VERSION ""

NS_ :

BS_:

BU_: ZCUR HCM_L HCM_R RLLM_Fix RRLM_Fix RLM_Move Trailer

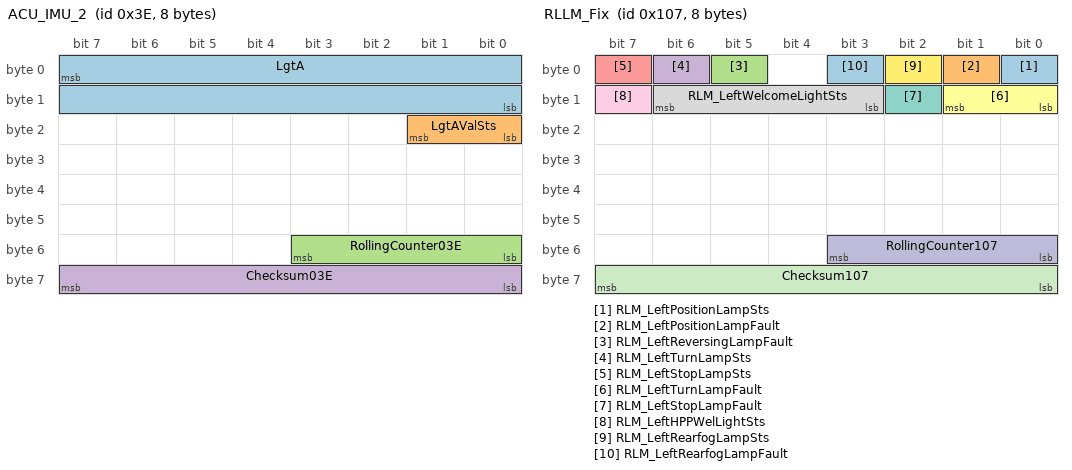
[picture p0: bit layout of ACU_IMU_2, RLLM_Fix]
BO_ 62 ACU_IMU_2: 8 ZCUR
 SG_ LgtA : 7|16@0+ (0.001,-2) [-2|2] "g" HCM_L,HCM_R
 SG_ LgtAValSts : 17|2@0+ (1,0) [0|3] "" HCM_L,HCM_R
 SG_ RollingCounter03E : 51|4@0+ (1,0) [0|15] "" HCM_L,HCM_R
 SG_ Checksum03E : 63|8@0+ (1,0) [0|255] "" HCM_L,HCM_R

BO_ 98 BCM_state3: 8 ZCUR
 SG_ BCM_AdasBlueLampReq : 1|2@0+ (1,0) [0|3] "" RLLM_Fix,RRLM_Fix,RLM_Move

BO_ 256 HCM_L: 8 HCM_L
 SG_ HCM_LeftpositionLampSts : 0|1@0+ (1,0) [0|1] "" ZCUR
 SG_ HCM_LeftpositionLampFault : 1|1@0+ (1,0) [0|1] "" ZCUR
 SG_ HCM_LeftDRLSts : 2|1@0+ (1,0) [0|1] "" ZCUR
 SG_ HCM_LeftDRLFault : 3|1@0+ (1,0) [0|1] "" ZCUR
 SG_ HCM_middleLeftPositionLampSts : 4|1@0+ (1,0) [0|1] "" ZCUR
 SG_ HCM_middleLeftPositionLampFault : 5|1@0+ (1,0) [0|1] "" ZCUR
 SG_ HCM_LeftLowBeamSts : 6|1@0+ (1,0) [0|1] "" ZCUR
 SG_ HCM_LeftLowBeamFault : 7|1@0+ (1,0) [0|1] "" ZCUR
 SG_ HCM_LeftHighBeamSts : 8|1@0+ (1,0) [0|1] "" ZCUR
 SG_ HCM_LeftHighBeamFault : 9|1@0+ (1,0) [0|1] "" ZCUR
 SG_ HCM_hcmHeightSetLt : 12|3@0+ (1,0) [0|7] "" ZCUR
 SG_ HCM_LeftTurnLampSts : 13|1@0+ (1,0) [0|1] "" ZCUR
 SG_ HCM_LeftTurnLampFault : 15|2@0+ (1,0) [0|3] "" ZCUR
 SG_ HCM_LeftWelcomeLightSts : 19|4@0+ (1,0) [0|15] "" ZCUR
 SG_ HCM_leftADBModeSts : 21|2@0+ (1,0) [0|3] "" ZCUR
 SG_ HCM_middleRightPositionLampFault : 22|1@0+ (1,0) [0|1] "" ZCUR
 SG_ HCM_middleRightPositionLampSts : 23|1@0+ (1,0) [0|1] "" ZCUR
 SG_ HCM_LeftInputVoltage : 29|6@0+ (1,0) [6|63] "V" ZCUR
 SG_ HCM_LeftHPPWelLightSts : 31|1@0+ (1,0) [0|1] "" ZCUR
 SG_ HCM_LeftMatrixLEDunitFault : 32|1@0+ (1,0) [0|1] "" ZCUR
 SG_ HCM_LeftAutoHeightAdjustFault : 33|1@0+ (1,0) [0|1] "" ZCUR
 SG_ HCM_LeftAFSFault : 34|1@0+ (1,0) [0|1] "" ZCUR
 SG_ HCM_WelcomeMusicEnable : 36|2@0+ (1,0) [0|3] "" ZCUR
 SG_ HCM_AlsHeightSet : 47|8@0+ (1,0) [0|255] "" ZCUR,HCM_R
 SG_ RollingCounter100 : 51|4@0+ (1,0) [0|15] "" ZCUR
 SG_ Checksum100 : 63|8@0+ (1,0) [0|255] "" ZCUR
 SG_ HCM_FLFogLampSts : 52|1@0+ (1,0) [0|1] "" ZCUR
 SG_ HCM_FLFogLampFault : 53|1@0+ (1,0) [0|1] "" ZCUR

BO_ 263 RLLM_Fix: 8 RLLM_Fix
 SG_ RLM_LeftPositionLampSts : 0|1@0+ (1,0) [0|1] "" ZCUR,RRLM_Fix
 SG_ RLM_LeftPositionLampFault : 1|1@0+ (1,0) [0|1] "" ZCUR,RRLM_Fix
 SG_ RLM_LeftReversingLampFault : 5|1@0+ (1,0) [0|1] "" ZCUR,RRLM_Fix
 SG_ RLM_LeftTurnLampSts : 6|1@0+ (1,0) [0|1] "" ZCUR,RRLM_Fix
 SG_ RLM_LeftStopLampSts : 7|1@0+ (1,0) [0|1] "" ZCUR,RRLM_Fix
 SG_ RLM_LeftTurnLampFault : 9|2@0+ (1,0) [0|3] "" ZCUR,RRLM_Fix
 SG_ RLM_LeftStopLampFault : 10|1@0+ (1,0) [0|1] "" ZCUR,RRLM_Fix
 SG_ RLM_LeftWelcomeLightSts : 14|4@0+ (1,0) [0|15] "" ZCUR,RRLM_Fix
 SG_ RLM_LeftHPPWelLightSts : 15|1@0+ (1,0) [0|1] "" ZCUR,RRLM_Fix
 SG_ RollingCounter107 : 51|4@0+ (1,0) [0|15] "" ZCUR
 SG_ Checksum107 : 63|8@0+ (1,0) [0|255] "" ZCUR
 SG_ RLM_LeftRearfogLampSts : 2|1@0+ (1,0) [0|1] "" ZCUR
 SG_ RLM_LeftRearfogLampFault : 3|1@0+ (1,0) [0|1] "" ZCUR

BO_ 264 RLM_Move: 8 RLM_Move
 SG_ RLM_MidpositionLampSts : 0|1@0+ (1,0) [0|1] "" ZCUR,RLLM_Fix,RRLM_Fix
 SG_ RLM_MidApositionLampFault : 1|1@0+ (1,0) [0|1] "" ZCUR,RLLM_Fix,RRLM_Fix
 SG_ RLM_MidLeftTurnLampSts : 2|1@0+ (1,0) [0|1] "" ZCUR,RLLM_Fix,RRLM_Fix
 SG_ RLM_MidStopLampSts : 3|1@0+ (1,0) [0|1] "" ZCUR,RLLM_Fix,RRLM_Fix
 SG_ RLM_MidLeftTurnLampFault : 5|2@0+ (1,0) [0|3] "" ZCUR,RLLM_Fix,RRLM_Fix
 SG_ RLM_MidLeftStopLampFault : 6|1@0+ (1,0) [0|1] "" ZCUR,RLLM_Fix,RRLM_Fix
 SG_ RLM_MidRightTurnLampSts : 7|1@0+ (1,0) [0|1] "" ZCUR,RLLM_Fix,RRLM_Fix
 SG_ RLM_LicenseLampFault : 8|1@0+ (1,0) [0|1] "" ZCUR,RLLM_Fix,RRLM_Fix
 SG_ RLM_LicenseLampSts : 9|1@0+ (1,0) [0|1] "" ZCUR,RLLM_Fix,RRLM_Fix
 SG_ RLM_ReversingLampFault : 10|1@0+ (1,0) [0|1] "" ZCUR,RLLM_Fix,RRLM_Fix
 SG_ RLM_ReverseLampSts : 11|1@0+ (1,0) [0|1] "" ZCUR,RLLM_Fix,RRLM_Fix
 SG_ RLM_HighStopLampFault : 12|1@0+ (1,0) [0|1] "" ZCUR,RLLM_Fix,RRLM_Fix
 SG_ RLM_HighStopLampSts : 13|1@0+ (1,0) [0|1] "" ZCUR,RLLM_Fix,RRLM_Fix
 SG_ RLM_MidRightTurnLampFault : 15|2@0+ (1,0) [0|3] "" ZCUR,RLLM_Fix,RRLM_Fix
 SG_ RLM_HPPWelLightSts : 19|1@0+ (1,0) [0|1] "" ZCUR,RLLM_Fix,RRLM_Fix
 SG_ RLM_WelcomeLightSts : 23|4@0+ (1,0) [0|15] "" ZCUR,RLLM_Fix,RRLM_Fix
 SG_ RLM_MidRightPositionLampSts : 18|1@0+ (1,0) [0|1] "" ZCUR
 SG_ RLM_MidRightPositionLampFault : 17|1@0+ (1,0) [0|1] "" ZCUR
 SG_ RollingCounter108 : 51|4@0+ (1,0) [0|15] "" ZCUR
 SG_ Checksum108 : 63|8@0+ (1,0) [0|255] "" ZCUR

BO_ 272 HCM_R: 8 HCM_R
 SG_ HCM_RightpositionLampSts : 0|1@0+ (1,0) [0|1] "" ZCUR
 SG_ HCM_RightpositionLampFault : 1|1@0+ (1,0) [0|1] "" ZCUR
 SG_ HCM_RightDRLSts : 2|1@0+ (1,0) [0|1] "" ZCUR
 SG_ HCM_RightDRLFault : 3|1@0+ (1,0) [0|1] "" ZCUR
 SG_ HCM_RightLowBeamSts : 6|1@0+ (1,0) [0|1] "" ZCUR
 SG_ HCM_RightLowBeamFault : 7|1@0+ (1,0) [0|1] "" ZCUR
 SG_ HCM_RightHighBeamSts : 8|1@0+ (1,0) [0|1] "" ZCUR
 SG_ HCM_RightHighBeamFault : 9|1@0+ (1,0) [0|1] "" ZCUR
 SG_ HCM_hcmHeightSetRt : 12|3@0+ (1,0) [0|7] "" ZCUR
 SG_ HCM_RightTurnLampSts : 13|1@0+ (1,0) [0|1] "" ZCUR
 SG_ HCM_RightTurnLampFault : 15|2@0+ (1,0) [0|3] "" ZCUR
 SG_ HCM_RightHPPWelLightSts : 17|1@0+ (1,0) [0|1] "" ZCUR
 SG_ HCM_RightWelcomeLightSts : 21|4@0+ (1,0) [0|15] "" ZCUR
 SG_ HCM_rightADBModeSts : 23|2@0+ (1,0) [0|3] "" ZCUR
 SG_ HCM_RightMatrixLEDunitFault : 24|1@0+ (1,0) [0|1] "" ZCUR
 SG_ HCM_RightAutoHeightAdjustFault : 25|1@0+ (1,0) [0|1] "" ZCUR
 SG_ HCM_RightAFSFault : 26|1@0+ (1,0) [0|1] "" ZCUR
 SG_ HCM_RightInputVoltage : 37|6@0+ (1,0) [6|63] "V" ZCUR
 SG_ RollingCounter110 : 51|4@0+ (1,0) [0|15] "" ZCUR
 SG_ Checksum110 : 63|8@0+ (1,0) [0|255] "" ZCUR
 SG_ HCM_FRFogLampSts : 27|1@0+ (1,0) [0|1] "" ZCUR
 SG_ HCM_FRFogLampFault : 28|1@0+ (1,0) [0|1] "" ZCUR

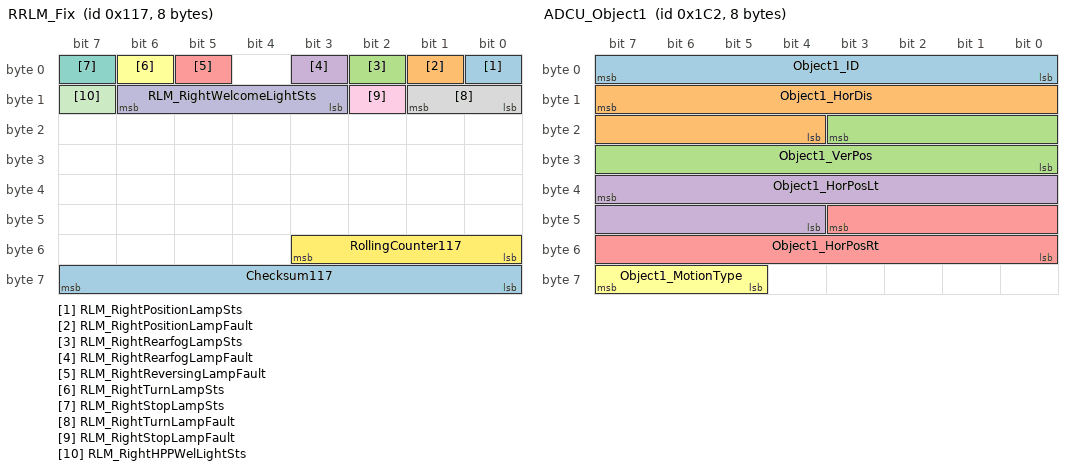
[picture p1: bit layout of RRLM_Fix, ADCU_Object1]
BO_ 279 RRLM_Fix: 8 RRLM_Fix
 SG_ RLM_RightPositionLampSts : 0|1@0+ (1,0) [0|1] "" ZCUR,RLM_Move
 SG_ RLM_RightPositionLampFault : 1|1@0+ (1,0) [0|1] "" ZCUR,RLM_Move
 SG_ RLM_RightRearfogLampSts : 2|1@0+ (1,0) [0|1] "" ZCUR,RLM_Move
 SG_ RLM_RightRearfogLampFault : 3|1@0+ (1,0) [0|1] "" ZCUR,RLM_Move
 SG_ RLM_RightReversingLampFault : 5|1@0+ (1,0) [0|1] "" ZCUR,RLM_Move
 SG_ RLM_RightTurnLampSts : 6|1@0+ (1,0) [0|1] "" ZCUR,RLM_Move
 SG_ RLM_RightStopLampSts : 7|1@0+ (1,0) [0|1] "" ZCUR,RLM_Move
 SG_ RLM_RightTurnLampFault : 9|2@0+ (1,0) [0|3] "" ZCUR,RLM_Move
 SG_ RLM_RightStopLampFault : 10|1@0+ (1,0) [0|1] "" ZCUR,RLM_Move
 SG_ RLM_RightWelcomeLightSts : 14|4@0+ (1,0) [0|15] "" ZCUR,RLM_Move
 SG_ RLM_RightHPPWelLightSts : 15|1@0+ (1,0) [0|1] "" ZCUR,RLM_Move
 SG_ RollingCounter117 : 51|4@0+ (1,0) [0|15] "" ZCUR,RLM_Move
 SG_ Checksum117 : 63|8@0+ (1,0) [0|255] "" ZCUR,RLM_Move

BO_ 450 ADCU_Object1: 8 ZCUR
 SG_ Object1_ID : 7|8@0+ (1,0) [0|250] "" HCM_L,HCM_R
 SG_ Object1_HorDis : 15|12@0+ (0.1,-30) [-30|30] "m" HCM_L,HCM_R
 SG_ Object1_VerPos : 19|12@0+ (0.2,0) [0|800] "m" HCM_L,HCM_R
 SG_ Object1_HorPosLt : 39|12@0+ (0.02,-40) [-40|40] "degree" HCM_L,HCM_R
 SG_ Object1_HorPosRt : 43|12@0+ (0.02,-40) [-40|40] "degree" HCM_L,HCM_R
 SG_ Object1_MotionType : 63|3@0+ (1,0) [0|7] "" HCM_L,HCM_R

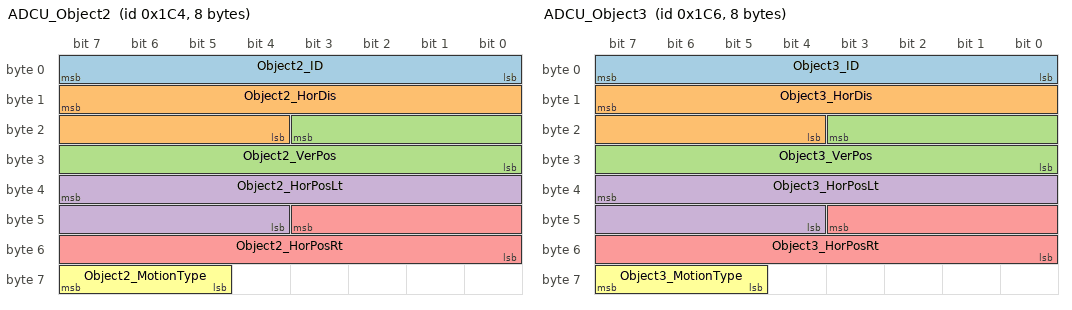
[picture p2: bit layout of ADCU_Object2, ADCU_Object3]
BO_ 452 ADCU_Object2: 8 ZCUR
 SG_ Object2_ID : 7|8@0+ (1,0) [0|250] "" HCM_L,HCM_R
 SG_ Object2_HorDis : 15|12@0+ (0.1,-30) [-30|30] "m" HCM_L,HCM_R
 SG_ Object2_VerPos : 19|12@0+ (0.2,0) [0|800] "m" HCM_L,HCM_R
 SG_ Object2_HorPosLt : 39|12@0+ (0.02,-40) [-40|40] "degree" HCM_L,HCM_R
 SG_ Object2_HorPosRt : 43|12@0+ (0.02,-40) [-40|40] "degree" HCM_L,HCM_R
 SG_ Object2_MotionType : 63|3@0+ (1,0) [0|7] "" HCM_L,HCM_R

BO_ 454 ADCU_Object3: 8 ZCUR
 SG_ Object3_ID : 7|8@0+ (1,0) [0|250] "" HCM_L,HCM_R
 SG_ Object3_HorDis : 15|12@0+ (0.1,-30) [-30|30] "m" HCM_L,HCM_R
 SG_ Object3_VerPos : 19|12@0+ (0.2,0) [0|800] "m" HCM_L,HCM_R
 SG_ Object3_HorPosLt : 39|12@0+ (0.02,-40) [-40|40] "degree" HCM_L,HCM_R
 SG_ Object3_HorPosRt : 43|12@0+ (0.02,-40) [-40|40] "degree" HCM_L,HCM_R
 SG_ Object3_MotionType : 63|3@0+ (1,0) [0|7] "" HCM_L,HCM_R

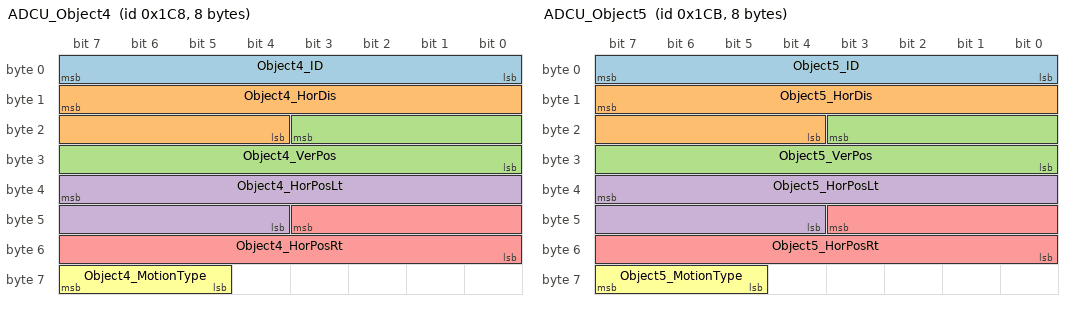
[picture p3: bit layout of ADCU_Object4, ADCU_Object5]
BO_ 456 ADCU_Object4: 8 ZCUR
 SG_ Object4_ID : 7|8@0+ (1,0) [0|250] "" HCM_L,HCM_R
 SG_ Object4_HorDis : 15|12@0+ (0.1,-30) [-30|30] "m" HCM_L,HCM_R
 SG_ Object4_VerPos : 19|12@0+ (0.2,0) [0|800] "m" HCM_L,HCM_R
 SG_ Object4_HorPosLt : 39|12@0+ (0.02,-40) [-40|40] "degree" HCM_L,HCM_R
 SG_ Object4_HorPosRt : 43|12@0+ (0.02,-40) [-40|40] "degree" HCM_L,HCM_R
 SG_ Object4_MotionType : 63|3@0+ (1,0) [0|7] "" HCM_L,HCM_R

BO_ 459 ADCU_Object5: 8 ZCUR
 SG_ Object5_ID : 7|8@0+ (1,0) [0|250] "" HCM_L,HCM_R
 SG_ Object5_HorDis : 15|12@0+ (0.1,-30) [-30|30] "m" HCM_L,HCM_R
 SG_ Object5_VerPos : 19|12@0+ (0.2,0) [0|800] "m" HCM_L,HCM_R
 SG_ Object5_HorPosLt : 39|12@0+ (0.02,-40) [-40|40] "degree" HCM_L,HCM_R
 SG_ Object5_HorPosRt : 43|12@0+ (0.02,-40) [-40|40] "degree" HCM_L,HCM_R
 SG_ Object5_MotionType : 63|3@0+ (1,0) [0|7] "" HCM_L,HCM_R

BO_ 471 IVI_ACHCMCtrl: 8 ZCUR
 SG_ ivi_hcmHeightSet : 47|3@0+ (1,0) [0|7] "" HCM_L,HCM_R
 SG_ IVI_hcmHeightAdjustSet : 54|2@0+ (1,0) [0|3] "" HCM_L,HCM_R

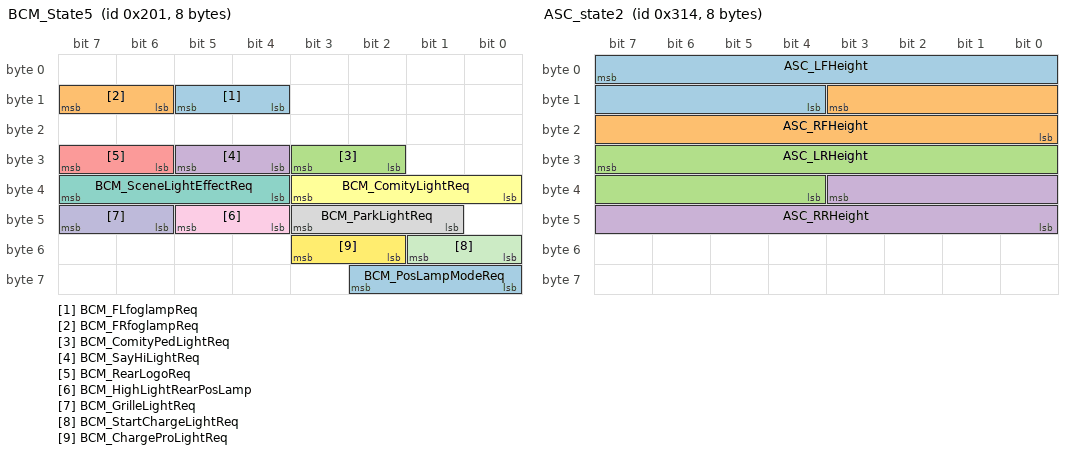
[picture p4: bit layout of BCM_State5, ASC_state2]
BO_ 513 BCM_State5: 8 ZCUR
 SG_ BCM_FLfoglampReq : 13|2@0+ (1,0) [0|3] "" HCM_L
 SG_ BCM_FRfoglampReq : 15|2@0+ (1,0) [0|3] "" HCM_R
 SG_ BCM_ComityPedLightReq : 27|2@0+ (1,0) [0|3] "" HCM_L,HCM_R,RLLM_Fix,RRLM_Fix,RLM_Move
 SG_ BCM_SayHiLightReq : 29|2@0+ (1,0) [0|3] "" HCM_L,HCM_R,RLLM_Fix,RRLM_Fix,RLM_Move
 SG_ BCM_RearLogoReq : 31|2@0+ (1,0) [0|3] "" RLM_Move
 SG_ BCM_ComityLightReq : 35|4@0+ (1,0) [0|15] "" HCM_L,HCM_R,RLLM_Fix,RRLM_Fix,RLM_Move
 SG_ BCM_SceneLightEffectReq : 39|4@0+ (1,0) [0|15] "" HCM_L,HCM_R,RLLM_Fix,RRLM_Fix,RLM_Move
 SG_ BCM_ParkLightReq : 43|3@0+ (1,0) [0|7] "" HCM_L,HCM_R,RLLM_Fix,RRLM_Fix,RLM_Move
 SG_ BCM_HighLightRearPosLamp : 45|2@0+ (1,0) [0|3] "" RLLM_Fix,RRLM_Fix,RLM_Move
 SG_ BCM_GrilleLightReq : 47|2@0+ (1,0) [0|3] "" Vector__XXX
 SG_ BCM_StartChargeLightReq : 49|2@0+ (1,0) [0|3] "" HCM_L,HCM_R,RLLM_Fix,RRLM_Fix,RLM_Move
 SG_ BCM_ChargeProLightReq : 51|2@0+ (1,0) [0|3] "" HCM_L,HCM_R,RLLM_Fix,RRLM_Fix,RLM_Move
 SG_ BCM_PosLampModeReq : 58|3@0+ (1,0) [0|7] "" RLLM_Fix,RRLM_Fix,RLM_Move

BO_ 673 BCM_state: 8 ZCUR
 SG_ BCM_RMPosLampReq : 1|2@0+ (1,0) [0|3] "" RLM_Move
 SG_ BCM_FLdrlReq : 3|2@0+ (1,0) [0|3] "" HCM_L
 SG_ BCM_EXLHeightAdjtReq : 11|3@0+ (1,0) [0|7] "" HCM_L,HCM_R
 SG_ BCM_ADBModeReq : 13|2@0+ (1,0) [0|3] "" HCM_L,HCM_R
 SG_ BCM_FLPosLampReq : 15|2@0+ (1,0) [0|3] "" HCM_L,HCM_R
 SG_ BCM_FRdrlReq : 17|2@0+ (1,0) [0|3] "" HCM_R
 SG_ BCM_FRPosLampReq : 19|2@0+ (1,0) [0|3] "" HCM_L,HCM_R
 SG_ BCM_LowBeamReq : 21|2@0+ (1,0) [0|3] "" HCM_L,HCM_R
 SG_ BCM_HighBeamReq : 23|2@0+ (1,0) [0|3] "" HCM_L,HCM_R
 SG_ BCM_RearfoglampReq : 27|2@0+ (1,0) [0|3] "" RRLM_Fix,Trailer
 SG_ BCM_LeftTurnLampReq : 29|2@0+ (1,0) [0|3] "" HCM_L,RLLM_Fix,RLM_Move,Trailer
 SG_ BCM_RightTurnLampReq : 31|2@0+ (1,0) [0|3] "" HCM_R,RRLM_Fix,RLM_Move,Trailer
 SG_ BCM_RLPosLampReq : 33|2@0+ (1,0) [0|3] "" RLLM_Fix,Trailer
 SG_ BCM_RRPosLampReq : 35|2@0+ (1,0) [0|3] "" RRLM_Fix,Trailer
 SG_ BCM_turnLampFlickerReq : 37|2@0+ (1,0) [0|3] "" HCM_L,HCM_R,RLLM_Fix,RRLM_Fix,RLM_Move
 SG_ BCM_turnLampSerialReq : 39|2@0+ (1,0) [0|3] "" HCM_L,HCM_R,RLLM_Fix,RRLM_Fix,RLM_Move
 SG_ BCM_ReversinglampReq : 41|2@0+ (1,0) [0|3] "" RLM_Move
 SG_ BCM_StoplampReq : 43|2@0+ (1,0) [0|3] "" RLLM_Fix,RRLM_Fix,RLM_Move,Trailer
 SG_ BCM_LicenseLampReq : 45|2@0+ (1,0) [0|3] "" RLM_Move
 SG_ RollingCounter2A1 : 51|4@0+ (1,0) [0|15] "" HCM_L,HCM_R,RLLM_Fix,RRLM_Fix,RLM_Move
 SG_ Checksum2A1 : 63|8@0+ (1,0) [0|255] "" HCM_L,HCM_R,RLLM_Fix,RRLM_Fix,RLM_Move

BO_ 675 BCM_state1: 8 ZCUR
 SG_ BCM_TurnAssistanceLamp : 52|1@0+ (1,0) [0|1] "" HCM_L
 SG_ BCM_PreviewLightEnable : 53|1@0+ (1,0) [0|1] "" HCM_L,HCM_R,RLLM_Fix,RRLM_Fix,RLM_Move

BO_ 682 PDCM5: 8 ZCUR
 SG_ HVCM_ChargeState : 31|5@0+ (1,0) [0|31] "" HCM_L,HCM_R,RLLM_Fix,RRLM_Fix,RLM_Move

BO_ 687 GW_BCM_DCU_CHA: 8 ZCUR
 SG_ bcm_frontWiperSts_0x2AF : 7|3@0+ (1,0) [0|7] "" HCM_L,HCM_R

BO_ 705 BCM_peps: 8 ZCUR
 SG_ bcm_pepsPowerMode : 2|3@0+ (1,0) [0|7] "" HCM_L,HCM_R,RLLM_Fix,RRLM_Fix,RLM_Move,Trailer

BO_ 788 ASC_state2: 8 ZCUR
 SG_ ASC_LFHeight : 7|12@0+ (0.1,-150) [-150|150] "mm" HCM_L,HCM_R
 SG_ ASC_RFHeight : 11|12@0+ (0.1,-150) [-150|150] "mm" HCM_L,HCM_R
 SG_ ASC_LRHeight : 31|12@0+ (0.1,-150) [-150|150] "mm" HCM_L,HCM_R
 SG_ ASC_RRHeight : 35|12@0+ (0.1,-150) [-150|150] "mm" HCM_L,HCM_R

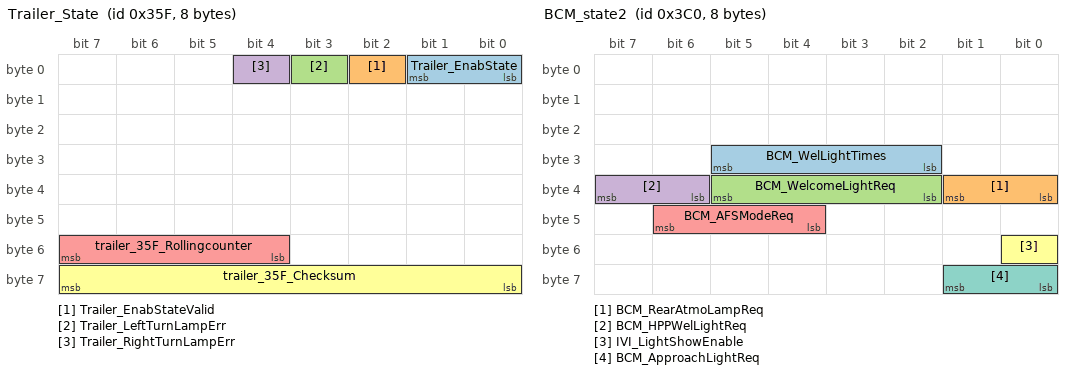
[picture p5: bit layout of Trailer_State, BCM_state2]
BO_ 863 Trailer_State: 8 Trailer
 SG_ Trailer_EnabState : 1|2@0+ (1,0) [0|3] "" ZCUR
 SG_ Trailer_EnabStateValid : 2|1@0+ (1,0) [0|1] "" ZCUR
 SG_ Trailer_LeftTurnLampErr : 3|1@0+ (1,0) [0|1] "" ZCUR
 SG_ Trailer_RightTurnLampErr : 4|1@0+ (1,0) [0|1] "" ZCUR
 SG_ trailer_35F_Rollingcounter : 55|4@0+ (1,0) [0|15] "" ZCUR
 SG_ trailer_35F_Checksum : 63|8@0+ (1,0) [0|255] "" ZCUR

BO_ 916 POT_state: 8 ZCUR
 SG_ pot_tailgateOpenSts : 7|3@0+ (1,0) [0|7] "" RLLM_Fix,RRLM_Fix,RLM_Move

BO_ 960 BCM_state2: 8 ZCUR
 SG_ BCM_WelLightTimes : 29|4@0+ (1,0) [0|15] "" HCM_L,HCM_R,RLLM_Fix,RRLM_Fix,RLM_Move
 SG_ BCM_RearAtmoLampReq : 33|2@0+ (1,0) [0|3] "" HCM_L,HCM_R,RLLM_Fix,RRLM_Fix,RLM_Move
 SG_ BCM_WelcomeLightReq : 37|4@0+ (1,0) [0|15] "" HCM_L,HCM_R,RLLM_Fix,RRLM_Fix,RLM_Move
 SG_ BCM_HPPWelLightReq : 39|2@0+ (1,0) [0|3] "" HCM_L,HCM_R,RLLM_Fix,RRLM_Fix,RLM_Move
 SG_ BCM_AFSModeReq : 46|3@0+ (1,0) [0|7] "" HCM_L,HCM_R
 SG_ IVI_LightShowEnable : 48|1@0+ (1,0) [0|1] "" HCM_L,HCM_R,RLLM_Fix,RRLM_Fix,RLM_Move
 SG_ BCM_ApproachLightReq : 57|2@0+ (1,0) [0|3] "" HCM_L,HCM_R,RLLM_Fix,RRLM_Fix,RLM_Move

BO_ 995 GW_EBS1: 8 ZCUR
 SG_ ebs_U_BATT : 7|14@0+ (0.0009765625,3) [3|18] "V" RLLM_Fix,RRLM_Fix,RLM_Move

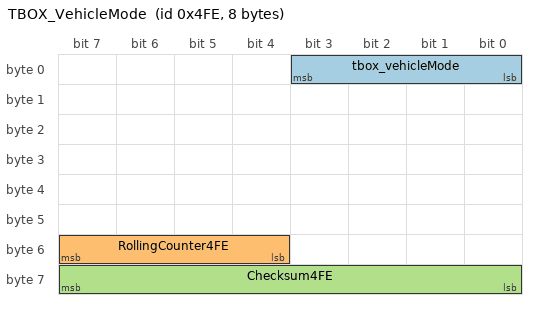
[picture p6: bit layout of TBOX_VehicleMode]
BO_ 1278 TBOX_VehicleMode: 8 ZCUR
 SG_ tbox_vehicleMode : 3|4@0+ (1,0) [0|15] "" HCM_L,HCM_R,RLLM_Fix,RRLM_Fix,RLM_Move
 SG_ RollingCounter4FE : 55|4@0+ (1,0) [0|15] "" HCM_L,HCM_R,RLLM_Fix,RRLM_Fix,RLM_Move
 SG_ Checksum4FE : 63|8@0+ (1,0) [0|255] "" HCM_L,HCM_R,RLLM_Fix,RRLM_Fix,RLM_Move

BO_ 1821 DiagReq_RLM_Move: 8 ZCUR
 SG_ RLM_Move_DiagReq : 7|64@0+ (1,0) [0|1] "" RLM_Move

BO_ 1823 DiagReq_RRLM_Fix: 8 ZCUR
 SG_ RRLM_Fix_DiagReq : 7|64@0+ (1,0) [0|1] "" RRLM_Fix

BO_ 1824 DiagReq_HCM_R: 8 ZCUR
 SG_ HCM_R_DiagReq : 7|64@0+ (1,0) [0|1] "" HCM_R

BO_ 1825 DiagReq_HCM_L: 8 ZCUR
 SG_ HCM_L_DiagReq : 7|64@0+ (1,0) [0|1] "" HCM_L

BO_ 1839 DiagReq_RLLM_Fix: 8 ZCUR
 SG_ RLLM_Fix_DiagReq : 7|64@0+ (1,0) [0|1] "" RLLM_Fix

BO_ 1854 Diag_PhyReq_Trailer: 8 ZCUR
 SG_ Trailer_Diag_PhyReq : 7|64@0+ (1,0) [0|1] "" Trailer

BO_ 1949 DiagResp_RLM_Move: 8 RLM_Move
 SG_ RLM_Move_DiagResp : 7|64@0+ (1,0) [0|1] "" ZCUR

BO_ 1951 DiagResp_RRLM_Fix: 8 RRLM_Fix
 SG_ RRLM_Fix_DiagResp : 7|64@0+ (1,0) [0|1] "" ZCUR

BO_ 1952 DiagResp_HCM_R: 8 HCM_R
 SG_ HCM_R_DiagResp : 7|64@0+ (1,0) [0|1] "" ZCUR

BO_ 1953 DiagResp_HCM_L: 8 HCM_L
 SG_ HCM_L_DiagResp : 7|64@0+ (1,0) [0|1] "" ZCUR

BO_ 1967 DiagResp_RLLM_Fix: 8 RLLM_Fix
 SG_ RLLM_Fix_DiagResp : 7|64@0+ (1,0) [0|1] "" ZCUR

BO_ 1982 Diag_Resp_Trailer: 8 Trailer
 SG_ Trailer_Diag_Resp : 7|64@0+ (1,0) [0|1] "" ZCUR

BO_ 2015 DiagReq_FUN: 8 ZCUR
 SG_ FUN_DiagReq : 7|64@0+ (1,0) [0|1] "" HCM_L,HCM_R,RLLM_Fix,RRLM_Fix,RLM_Move,Trailer

CM_ "该DBC由Vehicle.DB.Converter 1.0.25.0110 版本生成";
CM_ BO_ 471 "华为IVI发送";
CM_ BO_ 673 "ID冲突，
CDC/MDC所在网段发送BCM_state_HAW";
CM_ BO_ 788 "ASC→VIU-R→S32G_Mcore→VIU-F→CAN接收节点";
CM_ BO_ 916 "VCM发送";
CM_ BO_ 960 "需注意，此报文涉及华为方案，不能发到CDC/MDC涉及的网段，BCM_state2_HAW发给CDC/MDC接收";
CM_ BO_ 1278 "S32G发送（VMM域）";
CM_ BO_ 1821 "OBD→S32G_Mcore→VIU-F→RLM_Move";
CM_ BO_ 1823 "OBD→S32G_Mcore→VIU-F→RRLM_Fix";
CM_ BO_ 1824 "OBD→S32G_Mcore→VIU-F→HCM_R";
CM_ BO_ 1839 "OBD→S32G_Mcore→VIU-F→RLLM_Fix";
CM_ BO_ 1949 "RLM_Move→VIU-F→S32G_Mcore→OBD";
CM_ BO_ 1951 "RRLM_Fix→VIU-F→S32G_Mcore→OBD";
CM_ BO_ 1952 "HCM_R→VIU-F→S32G_Mcore→OBD";
CM_ BO_ 1953 "HCM_L→VIU-F→S32G_Mcore→OBD";
CM_ BO_ 1967 "RLLM_Fix→VIU-F→S32G_Mcore→OBD";
CM_ BO_ 2015 "报文路由_OBD→S32G_Mcore→TBOX/CAN接收节点_";
CM_ SG_ 62 LgtA "Longitudinal acceleration";
CM_ SG_ 62 LgtAValSts "Longitudinal acceleration value status";
CM_ SG_ 62 RollingCounter03E "every message increments the counter.";
CM_ SG_ 62 Checksum03E "CRC8 checksum.";
CM_ SG_ 98 BCM_AdasBlueLampReq "智驾小蓝灯请求";
CM_ SG_ 256 HCM_LeftpositionLampSts "左前位灯状态信号";
CM_ SG_ 256 HCM_LeftpositionLampFault "左前位置灯故障信号";
CM_ SG_ 256 HCM_LeftDRLSts "左昼间行驶灯状态信号";
CM_ SG_ 256 HCM_LeftDRLFault "左昼间行驶灯故障信号";
CM_ SG_ 256 HCM_middleLeftPositionLampSts "左前部中间位置灯状态信号";
CM_ SG_ 256 HCM_middleLeftPositionLampFault "左前部中间位置灯故障";
CM_ SG_ 256 HCM_LeftLowBeamSts "左近光灯状态信号";
CM_ SG_ 256 HCM_LeftLowBeamFault "左近光灯故障信号";
CM_ SG_ 256 HCM_LeftHighBeamSts "左远光灯状态信号";
CM_ SG_ 256 HCM_LeftHighBeamFault "左远光灯故障信号";
CM_ SG_ 256 HCM_hcmHeightSetLt "left hcm Height Set";
CM_ SG_ 256 HCM_LeftTurnLampSts "左前转向灯状态信号";
CM_ SG_ 256 HCM_LeftTurnLampFault "左前转向灯故障信号";
CM_ SG_ 256 HCM_LeftWelcomeLightSts "左前欢迎照明当前状态";
CM_ SG_ 256 HCM_leftADBModeSts "左前ADB模式状态";
CM_ SG_ 256 HCM_middleRightPositionLampFault "右前部中间位置灯故障信号";
CM_ SG_ 256 HCM_middleRightPositionLampSts "右前部中间位置灯状态信号";
CM_ SG_ 256 HCM_LeftInputVoltage "左前灯当前输入电压";
CM_ SG_ 256 HCM_LeftHPPWelLightSts "左前HPP迎宾灯状态";
CM_ SG_ 256 HCM_LeftMatrixLEDunitFault "左前矩阵LED模块故障";
CM_ SG_ 256 HCM_LeftAutoHeightAdjustFault "左前前照灯自动高度调节故障";
CM_ SG_ 256 HCM_LeftAFSFault "左前AFS故障状态";
CM_ SG_ 256 HCM_WelcomeMusicEnable "欢迎音效使能";
CM_ SG_ 256 HCM_AlsHeightSet "Als前灯当前高度";
CM_ SG_ 256 RollingCounter100 "every message increments the counter.";
CM_ SG_ 256 Checksum100 "CRC8, checksum.";
CM_ SG_ 256 HCM_FLFogLampSts "左前雾灯状态信号";
CM_ SG_ 256 HCM_FLFogLampFault "左前雾灯故障状态信号";
CM_ SG_ 263 RLM_LeftPositionLampSts "后左尾灯位置灯状态信号";
CM_ SG_ 263 RLM_LeftPositionLampFault "后左尾灯位置灯故障信号";
CM_ SG_ 263 RLM_LeftReversingLampFault "左倒车灯故障信号（实际无发送，预留）";
CM_ SG_ 263 RLM_LeftTurnLampSts "左后转向灯状态信号";
CM_ SG_ 263 RLM_LeftStopLampSts "制动灯L状态信号";
CM_ SG_ 263 RLM_LeftTurnLampFault "左后转向灯故障信号";
CM_ SG_ 263 RLM_LeftStopLampFault "制动灯L故障信号";
CM_ SG_ 263 RLM_LeftWelcomeLightSts "左后欢迎照明当前状态";
CM_ SG_ 263 RLM_LeftHPPWelLightSts "左后HPP迎宾灯状态";
CM_ SG_ 263 RollingCounter107 "every message increments the counter.";
CM_ SG_ 263 Checksum107 "CRC8, checksum.";
CM_ SG_ 263 RLM_LeftRearfogLampSts "左后雾灯状态信号";
CM_ SG_ 263 RLM_LeftRearfogLampFault "左后雾灯故障信号";
CM_ SG_ 264 RLM_MidpositionLampSts "后中尾灯位置灯状态信号";
CM_ SG_ 264 RLM_MidApositionLampFault "后中尾灯位置灯故障信号";
CM_ SG_ 264 RLM_MidLeftTurnLampSts "尾灯中部左后转向灯状态信号";
CM_ SG_ 264 RLM_MidStopLampSts "制动灯状态信号";
CM_ SG_ 264 RLM_MidLeftTurnLampFault "尾灯中部左后转向灯故障信号";
CM_ SG_ 264 RLM_MidLeftStopLampFault "制动灯故障信号";
CM_ SG_ 264 RLM_MidRightTurnLampSts "尾灯中部右后转向灯状态信号";
CM_ SG_ 264 RLM_LicenseLampFault "牌照灯故障信号";
CM_ SG_ 264 RLM_LicenseLampSts "牌照灯状态";
CM_ SG_ 264 RLM_ReversingLampFault "倒车灯故障信号";
CM_ SG_ 264 RLM_ReverseLampSts "倒车灯状态信号";
CM_ SG_ 264 RLM_HighStopLampFault "高位制动灯故障信号";
CM_ SG_ 264 RLM_HighStopLampSts "高位制动灯状态信号";
CM_ SG_ 264 RLM_MidRightTurnLampFault "尾灯中部右后转向灯故障信号";
CM_ SG_ 264 RLM_HPPWelLightSts "后部移动侧灯组HPP迎宾灯状态";
CM_ SG_ 264 RLM_WelcomeLightSts "后部移动侧灯组欢迎照明当前状态";
CM_ SG_ 264 RLM_MidRightPositionLampSts "后中尾灯右侧位置灯状态信号";
CM_ SG_ 264 RLM_MidRightPositionLampFault "后中尾灯右侧位置灯故障信号";
CM_ SG_ 264 RollingCounter108 "every message increments the counter.";
CM_ SG_ 264 Checksum108 "CRC8, checksum.";
CM_ SG_ 272 HCM_RightpositionLampSts "右前位灯状态信号";
CM_ SG_ 272 HCM_RightpositionLampFault "右前位置灯故障信号";
CM_ SG_ 272 HCM_RightDRLSts "右昼间行驶灯状态信号";
CM_ SG_ 272 HCM_RightDRLFault "右昼间行驶灯故障信号";
CM_ SG_ 272 HCM_RightLowBeamSts "右近光灯状态信号";
CM_ SG_ 272 HCM_RightLowBeamFault "右近光灯故障信号";
CM_ SG_ 272 HCM_RightHighBeamSts "右远光灯状态信号";
CM_ SG_ 272 HCM_RightHighBeamFault "右远光灯故障信号";
CM_ SG_ 272 HCM_hcmHeightSetRt "right hcm Height Set";
CM_ SG_ 272 HCM_RightTurnLampSts "右前转向灯状态信号";
CM_ SG_ 272 HCM_RightTurnLampFault "右前转向灯故障信号";
CM_ SG_ 272 HCM_RightHPPWelLightSts "右前HPP迎宾灯状态";
CM_ SG_ 272 HCM_RightWelcomeLightSts "右前欢迎照明当前状态";
CM_ SG_ 272 HCM_rightADBModeSts "右前ADB模式状态";
CM_ SG_ 272 HCM_RightMatrixLEDunitFault "右前矩阵LED模块故障";
CM_ SG_ 272 HCM_RightAutoHeightAdjustFault "右前前照灯自动高度调节故障";
CM_ SG_ 272 HCM_RightAFSFault "右前AFS故障状态";
CM_ SG_ 272 HCM_RightInputVoltage "右前灯当前输入电压";
CM_ SG_ 272 RollingCounter110 "every message increments the counter.";
CM_ SG_ 272 Checksum110 "CRC8, checksum.";
CM_ SG_ 272 HCM_FRFogLampSts "右前雾灯状态信号";
CM_ SG_ 272 HCM_FRFogLampFault "右前雾灯故障状态信号";
CM_ SG_ 279 RLM_RightPositionLampSts "后右尾灯位置灯状态信号";
CM_ SG_ 279 RLM_RightPositionLampFault "后右尾灯位置灯故障信号";
CM_ SG_ 279 RLM_RightRearfogLampSts "右后雾灯状态信号";
CM_ SG_ 279 RLM_RightRearfogLampFault "右后雾灯故障信号";
CM_ SG_ 279 RLM_RightReversingLampFault "右倒车灯故障信号";
CM_ SG_ 279 RLM_RightTurnLampSts "右后转向灯状态信号";
CM_ SG_ 279 RLM_RightStopLampSts "制动灯R状态信号";
CM_ SG_ 279 RLM_RightTurnLampFault "右后转向灯故障信号";
CM_ SG_ 279 RLM_RightStopLampFault "制动灯R故障信号";
CM_ SG_ 279 RLM_RightWelcomeLightSts "右后欢迎照明当前状态";
CM_ SG_ 279 RLM_RightHPPWelLightSts "右后HPP迎宾灯状态";
CM_ SG_ 279 RollingCounter117 "every message increments the counter.";
CM_ SG_ 279 Checksum117 "CRC8, checksum.";
CM_ SG_ 450 Object1_ID "目标1ID";
CM_ SG_ 450 Object1_HorDis "目标1横向距离";
CM_ SG_ 450 Object1_VerPos "目标1纵向距离";
CM_ SG_ 450 Object1_HorPosLt "目标1横向左边界";
CM_ SG_ 450 Object1_HorPosRt "目标1横向右边界";
CM_ SG_ 450 Object1_MotionType "目标1运动类型";
CM_ SG_ 452 Object2_ID "目标2ID";
CM_ SG_ 452 Object2_HorDis "目标2横向距离";
CM_ SG_ 452 Object2_VerPos "目标2纵向距离";
CM_ SG_ 452 Object2_HorPosLt "目标2横向左边界";
CM_ SG_ 452 Object2_HorPosRt "目标2横向右边界";
CM_ SG_ 452 Object2_MotionType "目标2运动类型";
CM_ SG_ 454 Object3_ID "目标3ID";
CM_ SG_ 454 Object3_HorDis "目标3横向距离";
CM_ SG_ 454 Object3_VerPos "目标3纵向距离";
CM_ SG_ 454 Object3_HorPosLt "目标3横向左边界";
CM_ SG_ 454 Object3_HorPosRt "目标3横向右边界";
CM_ SG_ 454 Object3_MotionType "目标3运动类型";
CM_ SG_ 456 Object4_ID "目标4ID";
CM_ SG_ 456 Object4_HorDis "目标4横向距离";
CM_ SG_ 456 Object4_VerPos "目标4纵向距离";
CM_ SG_ 456 Object4_HorPosLt "目标4横向左边界";
CM_ SG_ 456 Object4_HorPosRt "目标4横向右边界";
CM_ SG_ 456 Object4_MotionType "目标4运动类型";
CM_ SG_ 459 Object5_ID "目标5ID";
CM_ SG_ 459 Object5_HorDis "目标5横向距离";
CM_ SG_ 459 Object5_VerPos "目标5纵向距离";
CM_ SG_ 459 Object5_HorPosLt "目标5横向左边界";
CM_ SG_ 459 Object5_HorPosRt "目标5横向右边界";
CM_ SG_ 459 Object5_MotionType "目标5运动类型";
CM_ SG_ 471 ivi_hcmHeightSet "HCM height set.";
CM_ SG_ 471 IVI_hcmHeightAdjustSet "大灯高度自动调节使能";
CM_ SG_ 513 BCM_FLfoglampReq "左前雾灯请求";
CM_ SG_ 513 BCM_FRfoglampReq "右前雾灯请求";
CM_ SG_ 513 BCM_ComityPedLightReq "礼让行人灯效请求";
CM_ SG_ 513 BCM_SayHiLightReq "SayHi灯效请求";
CM_ SG_ 513 BCM_RearLogoReq "后logo灯请求";
CM_ SG_ 513 BCM_ComityLightReq "送宾灯效请求";
CM_ SG_ 513 BCM_SceneLightEffectReq "场景灯效请求";
CM_ SG_ 513 BCM_ParkLightReq "驻车灯效请求";
CM_ SG_ 513 BCM_HighLightRearPosLamp "高亮后位置灯请求";
CM_ SG_ 513 BCM_GrilleLightReq "格栅灯请求";
CM_ SG_ 513 BCM_StartChargeLightReq "开始充电灯效请求";
CM_ SG_ 513 BCM_ChargeProLightReq "充电进度灯效请求";
CM_ SG_ 513 BCM_PosLampModeReq "后位置灯样式请求";
CM_ SG_ 673 BCM_RMPosLampReq "后移动侧位置灯请求信号";
CM_ SG_ 673 BCM_FLdrlReq "左前昼间行驶灯请求信号";
CM_ SG_ 673 BCM_EXLHeightAdjtReq "大灯高度手动调节请求";
CM_ SG_ 673 BCM_ADBModeReq "ADB模式请求";
CM_ SG_ 673 BCM_FLPosLampReq "左前位置灯请求信号";
CM_ SG_ 673 BCM_FRdrlReq "右前昼间行驶灯请求信号";
CM_ SG_ 673 BCM_FRPosLampReq "右前位置灯请求信号";
CM_ SG_ 673 BCM_LowBeamReq "近光灯请求信号";
CM_ SG_ 673 BCM_HighBeamReq "远光灯请求信号";
CM_ SG_ 673 BCM_RearfoglampReq "后雾灯请求信号";
CM_ SG_ 673 BCM_LeftTurnLampReq "左转向灯请求信号";
CM_ SG_ 673 BCM_RightTurnLampReq "右转向灯请求信号";
CM_ SG_ 673 BCM_RLPosLampReq "左后位置灯请求信号";
CM_ SG_ 673 BCM_RRPosLampReq "右后位置灯请求信号";
CM_ SG_ 673 BCM_turnLampFlickerReq "转向灯闪烁频率请求";
CM_ SG_ 673 BCM_turnLampSerialReq "转向灯流水请求";
CM_ SG_ 673 BCM_ReversinglampReq "倒车灯请求信号";
CM_ SG_ 673 BCM_StoplampReq "制动灯请求信号";
CM_ SG_ 673 BCM_LicenseLampReq "牌照灯请求";
CM_ SG_ 673 RollingCounter2A1 "every message increments the counter.";
CM_ SG_ 673 Checksum2A1 "CRC8, checksum.";
CM_ SG_ 675 BCM_TurnAssistanceLamp "弯道辅助照明使能信号";
CM_ SG_ 675 BCM_PreviewLightEnable "预览灯效使能";
CM_ SG_ 682 HVCM_ChargeState "the currently charging state, used for display";
CM_ SG_ 687 bcm_frontWiperSts_0x2AF "Front wiper status.";
CM_ SG_ 705 bcm_pepsPowerMode "peps Power Mode.";
CM_ SG_ 788 ASC_LFHeight "Height of front left wheel.";
CM_ SG_ 788 ASC_RFHeight "Height of front right wheel.";
CM_ SG_ 788 ASC_LRHeight "Height of rear left wheel.";
CM_ SG_ 788 ASC_RRHeight "Height of rear right wheel.";
CM_ SG_ 863 Trailer_EnabState "挂车使能状态";
CM_ SG_ 863 Trailer_EnabStateValid "挂车使能状态有效位";
CM_ SG_ 863 Trailer_LeftTurnLampErr "挂车左转向灯故障";
CM_ SG_ 863 Trailer_RightTurnLampErr "挂车右转向灯故障";
CM_ SG_ 863 trailer_35F_Rollingcounter "Message counter for the message.";
CM_ SG_ 863 trailer_35F_Checksum "CRC8, message checksum.";
CM_ SG_ 916 pot_tailgateOpenSts "Tailgate open status.";
CM_ SG_ 960 BCM_WelLightTimes "欢迎灯光循环次数";
CM_ SG_ 960 BCM_RearAtmoLampReq "尾部氛围灯请求";
CM_ SG_ 960 BCM_WelcomeLightReq "欢迎照明请求";
CM_ SG_ 960 BCM_HPPWelLightReq "HPP迎宾灯请求";
CM_ SG_ 960 BCM_AFSModeReq "AFS模式请求";
CM_ SG_ 960 IVI_LightShowEnable "音乐灯光秀使能信号";
CM_ SG_ 960 BCM_ApproachLightReq "接近照明请求";
CM_ SG_ 995 ebs_U_BATT "Battery voltage";
CM_ SG_ 1278 tbox_vehicleMode "the signal indicates the current vehicle state to active or dective functions
_H53项目TBOX不需要处理此信号_";
CM_ SG_ 1278 RollingCounter4FE "every message increments the counter.
_H53项目TBOX不需要处理此信号_";
CM_ SG_ 1278 Checksum4FE "CRC8, message checksum.
_H53项目TBOX不需要处理此信号_";
CM_ SG_ 1821 RLM_Move_DiagReq "Diagnostic request";
CM_ SG_ 1823 RRLM_Fix_DiagReq "Diagnostic request";
CM_ SG_ 1824 HCM_R_DiagReq "Diagnostic request";
CM_ SG_ 1825 HCM_L_DiagReq "Diagnostic request";
CM_ SG_ 1839 RLLM_Fix_DiagReq "Diagnostic request";
CM_ SG_ 1854 Trailer_Diag_PhyReq "Diagnostic Physical Request Data to Trailer";
CM_ SG_ 1949 RLM_Move_DiagResp "Diagnostic response";
CM_ SG_ 1951 RRLM_Fix_DiagResp "Diagnostic response";
CM_ SG_ 1952 HCM_R_DiagResp "Diagnostic response";
CM_ SG_ 1953 HCM_L_DiagResp "Diagnostic response";
CM_ SG_ 1967 RLLM_Fix_DiagResp "Diagnostic response";
CM_ SG_ 1982 Trailer_Diag_Resp "Diagnostic Physical response Data from Trailer";
CM_ SG_ 2015 FUN_DiagReq "Diagnostic request";

BA_DEF_ BO_  "GenMsgSendType" ENUM  "Cyclic","Event","IfActive","CE","CA","NoMsgSendType";
BA_DEF_ BO_  "GenMsgCycleTime" INT 0 0;
BA_DEF_ SG_  "GenSigSendType" ENUM  "Cyclic","OnChange","OnWrite","IfActive","OnChangeWithRepetition","OnWriteWithRepetition","IfActiveWithRepetition","NoSigSendType","OnChangeAndIfActive","OnChangeAndIfActiveWithRepetition","CA","CE","Event";
BA_DEF_ SG_  "GenSigStartValue" INT 0 0;
BA_DEF_ BO_  "GenMsgCycleTimeFast" INT 0 0;
BA_DEF_ BO_  "GenMsgNrOfRepetition" INT 0 0;
BA_DEF_ BO_  "GenMsgDelayTime" INT 0 0;
BA_DEF_  "DBName" STRING ;
BA_DEF_ BU_  "NodeLayerModules" STRING ;
BA_DEF_ BU_  "NmNode" ENUM  "Not","Yes";
BA_DEF_  "NmBaseAddress" HEX 0 2047;
BA_DEF_ BO_  "GenMsgILSupport" ENUM  "No","Yes";
BA_DEF_  "BusType" STRING ;
BA_DEF_DEF_  "GenMsgSendType" "Cyclic";
BA_DEF_DEF_  "GenMsgCycleTime" 0;
BA_DEF_DEF_  "GenSigSendType" "Cyclic";
BA_DEF_DEF_  "GenSigStartValue" 0;
BA_DEF_DEF_  "GenMsgCycleTimeFast" 0;
BA_DEF_DEF_  "GenMsgNrOfRepetition" 0;
BA_DEF_DEF_  "GenMsgDelayTime" 0;
BA_DEF_DEF_  "DBName" "";
BA_DEF_DEF_  "NodeLayerModules" "CANoeILNLVector.dll";
BA_DEF_DEF_  "NmNode" "Not";
BA_DEF_DEF_  "NmBaseAddress" 1536;
BA_DEF_DEF_  "GenMsgILSupport" "Yes";
BA_DEF_DEF_  "BusType" "CAN";
BA_ "DBName" "H77_Matrix_ExLighting_CAN_v3.0.1";
BA_ "GenMsgCycleTime" BO_ 62 20;
BA_ "GenMsgCycleTime" BO_ 98 10;
BA_ "GenMsgCycleTime" BO_ 256 40;
BA_ "GenMsgCycleTime" BO_ 263 40;
BA_ "GenMsgCycleTime" BO_ 264 40;
BA_ "GenMsgCycleTime" BO_ 272 40;
BA_ "GenMsgCycleTime" BO_ 279 40;
BA_ "GenMsgCycleTime" BO_ 450 40;
BA_ "GenMsgCycleTime" BO_ 452 40;
BA_ "GenMsgCycleTime" BO_ 454 40;
BA_ "GenMsgCycleTime" BO_ 456 40;
BA_ "GenMsgCycleTime" BO_ 459 40;
BA_ "GenMsgSendType" BO_ 471 3;
BA_ "GenMsgCycleTime" BO_ 471 100;
BA_ "GenMsgCycleTimeFast" BO_ 471 20;
BA_ "GenMsgNrOfRepetition" BO_ 471 3;
BA_ "GenMsgDelayTime" BO_ 471 20;
BA_ "GenMsgCycleTime" BO_ 513 100;
BA_ "GenMsgCycleTime" BO_ 673 20;
BA_ "GenMsgCycleTime" BO_ 675 100;
BA_ "GenMsgCycleTime" BO_ 682 100;
BA_ "GenMsgCycleTime" BO_ 687 100;
BA_ "GenMsgCycleTime" BO_ 705 100;
BA_ "GenMsgCycleTime" BO_ 788 50;
BA_ "GenMsgCycleTime" BO_ 863 100;
BA_ "GenMsgCycleTime" BO_ 916 100;
BA_ "GenMsgSendType" BO_ 960 3;
BA_ "GenMsgCycleTime" BO_ 960 100;
BA_ "GenMsgCycleTimeFast" BO_ 960 20;
BA_ "GenMsgNrOfRepetition" BO_ 960 3;
BA_ "GenMsgDelayTime" BO_ 960 20;
BA_ "GenMsgCycleTime" BO_ 995 100;
BA_ "GenMsgCycleTime" BO_ 1278 1000;
BA_ "GenMsgSendType" BO_ 1821 1;
BA_ "GenMsgSendType" BO_ 1823 1;
BA_ "GenMsgSendType" BO_ 1824 1;
BA_ "GenMsgSendType" BO_ 1825 1;
BA_ "GenMsgSendType" BO_ 1839 1;
BA_ "GenMsgSendType" BO_ 1854 1;
BA_ "GenMsgSendType" BO_ 1949 1;
BA_ "GenMsgSendType" BO_ 1951 1;
BA_ "GenMsgSendType" BO_ 1952 1;
BA_ "GenMsgSendType" BO_ 1953 1;
BA_ "GenMsgSendType" BO_ 1967 1;
BA_ "GenMsgSendType" BO_ 1982 1;
BA_ "GenMsgSendType" BO_ 2015 1;
BA_ "GenSigStartValue" SG_ 62 LgtAValSts 3;
BA_ "GenSigStartValue" SG_ 256 HCM_LeftInputVoltage 13;
BA_ "GenSigStartValue" SG_ 256 HCM_AlsHeightSet 1;
BA_ "GenSigStartValue" SG_ 272 HCM_RightInputVoltage 13;
BA_ "GenSigStartValue" SG_ 450 Object1_HorDis 4094;
BA_ "GenSigStartValue" SG_ 450 Object1_VerPos 4094;
BA_ "GenSigStartValue" SG_ 450 Object1_HorPosLt 4094;
BA_ "GenSigStartValue" SG_ 450 Object1_HorPosRt 4094;
BA_ "GenSigStartValue" SG_ 452 Object2_HorDis 4094;
BA_ "GenSigStartValue" SG_ 452 Object2_VerPos 4094;
BA_ "GenSigStartValue" SG_ 452 Object2_HorPosLt 4094;
BA_ "GenSigStartValue" SG_ 452 Object2_HorPosRt 4094;
BA_ "GenSigStartValue" SG_ 454 Object3_HorDis 4094;
BA_ "GenSigStartValue" SG_ 454 Object3_VerPos 4094;
BA_ "GenSigStartValue" SG_ 454 Object3_HorPosLt 4094;
BA_ "GenSigStartValue" SG_ 454 Object3_HorPosRt 4094;
BA_ "GenSigStartValue" SG_ 456 Object4_HorDis 4094;
BA_ "GenSigStartValue" SG_ 456 Object4_VerPos 4094;
BA_ "GenSigStartValue" SG_ 456 Object4_HorPosLt 4094;
BA_ "GenSigStartValue" SG_ 456 Object4_HorPosRt 4094;
BA_ "GenSigStartValue" SG_ 459 Object5_HorDis 4094;
BA_ "GenSigStartValue" SG_ 459 Object5_VerPos 4094;
BA_ "GenSigStartValue" SG_ 459 Object5_HorPosLt 4094;
BA_ "GenSigStartValue" SG_ 459 Object5_HorPosRt 4094;
BA_ "GenSigSendType" SG_ 471 ivi_hcmHeightSet 4;
BA_ "GenSigSendType" SG_ 471 IVI_hcmHeightAdjustSet 4;
BA_ "GenSigStartValue" SG_ 682 HVCM_ChargeState 30;
BA_ "GenSigSendType" SG_ 960 IVI_LightShowEnable 4;
BA_ "GenSigStartValue" SG_ 995 ebs_U_BATT 16383;
BA_ "GenSigSendType" SG_ 1821 RLM_Move_DiagReq 2;
BA_ "GenSigSendType" SG_ 1823 RRLM_Fix_DiagReq 2;
BA_ "GenSigSendType" SG_ 1824 HCM_R_DiagReq 2;
BA_ "GenSigSendType" SG_ 1825 HCM_L_DiagReq 2;
BA_ "GenSigSendType" SG_ 1839 RLLM_Fix_DiagReq 2;
BA_ "GenSigSendType" SG_ 1854 Trailer_Diag_PhyReq 2;
BA_ "GenSigSendType" SG_ 1949 RLM_Move_DiagResp 2;
BA_ "GenSigSendType" SG_ 1951 RRLM_Fix_DiagResp 2;
BA_ "GenSigSendType" SG_ 1952 HCM_R_DiagResp 2;
BA_ "GenSigSendType" SG_ 1953 HCM_L_DiagResp 2;
BA_ "GenSigSendType" SG_ 1967 RLLM_Fix_DiagResp 2;
BA_ "GenSigSendType" SG_ 1982 Trailer_Diag_Resp 2;
BA_ "GenSigSendType" SG_ 2015 FUN_DiagReq 2;
VAL_ 62 LgtAValSts 0 "Invalid"1 "Valid"2 "Reserved"3 "Initializing";
VAL_ 98 BCM_AdasBlueLampReq 0 "No request"1 "OFF"2 "ON"3 "Reserved";
VAL_ 256 HCM_LeftpositionLampSts 0 "Off"1 "On";
VAL_ 256 HCM_LeftpositionLampFault 0 "good"1 "fault";
VAL_ 256 HCM_LeftDRLSts 0 "Off"1 "On";
VAL_ 256 HCM_LeftDRLFault 0 "good"1 "fault";
VAL_ 256 HCM_middleLeftPositionLampSts 0 "Off"1 "On";
VAL_ 256 HCM_middleLeftPositionLampFault 0 "good"1 "fault";
VAL_ 256 HCM_LeftLowBeamSts 0 "Off"1 "On";
VAL_ 256 HCM_LeftLowBeamFault 0 "good"1 "fault";
VAL_ 256 HCM_LeftHighBeamSts 0 "Off"1 "On";
VAL_ 256 HCM_LeftHighBeamFault 0 "good"1 "fault";
VAL_ 256 HCM_hcmHeightSetLt 0 "UNDEFINEDt"1 "Level 1"2 "Level 2"3 "Level 3"4 "Level 4"5 "Level 5"6 "Reserved"7 "Reserved";
VAL_ 256 HCM_LeftTurnLampSts 0 "Off"1 "On";
VAL_ 256 HCM_LeftTurnLampFault 0 "No Failure"1 "Short Circuit"2 "Open Circuit"3 "Reserved";
VAL_ 256 HCM_LeftWelcomeLightSts 0 "Default"1 "OFF"2 "Mode1"3 "Mode2"4 "Mode3"5 "Mode4"6 "Mode5"7 "Mode6"8 "Mode7"9 "Mode8"10 "Mode9"11 "Mode10"12 "Reserved"13 "Reserved"14 "Reserved"15 "Reserved";
VAL_ 256 HCM_leftADBModeSts 0 "Default"1 "OFF"2 "StandBy"3 "ON";
VAL_ 256 HCM_middleRightPositionLampFault 0 "good"1 "fault";
VAL_ 256 HCM_middleRightPositionLampSts 0 "Off"1 "On";
VAL_ 256 HCM_LeftInputVoltage 0 "Invalid"1 "Invalid"2 "Invalid"3 "Invalid"4 "Invalid"5 "Invalid"13 "13V";
VAL_ 256 HCM_LeftHPPWelLightSts 0 "Off"1 "On";
VAL_ 256 HCM_LeftMatrixLEDunitFault 0 "good"1 "fault";
VAL_ 256 HCM_LeftAutoHeightAdjustFault 0 "good"1 "fault";
VAL_ 256 HCM_LeftAFSFault 0 "good"1 "fault";
VAL_ 256 HCM_WelcomeMusicEnable 0 "No request"1 "OFF"2 "ON"3 "Reserved";
VAL_ 256 HCM_FLFogLampSts 0 "Off"1 "On";
VAL_ 256 HCM_FLFogLampFault 0 "good"1 "fault";
VAL_ 263 RLM_LeftPositionLampSts 0 "Off"1 "On";
VAL_ 263 RLM_LeftPositionLampFault 0 "good"1 "fault";
VAL_ 263 RLM_LeftReversingLampFault 0 "good"1 "fault";
VAL_ 263 RLM_LeftTurnLampSts 0 "Off"1 "On";
VAL_ 263 RLM_LeftStopLampSts 0 "Off"1 "On";
VAL_ 263 RLM_LeftTurnLampFault 0 "No Failure"1 "Short Circuit"2 "Open Circuit"3 "Reserved";
VAL_ 263 RLM_LeftStopLampFault 0 "good"1 "fault";
VAL_ 263 RLM_LeftWelcomeLightSts 0 "Default"1 "OFF"2 "Mode1"3 "Mode2"4 "Mode3"5 "Mode4"6 "Mode5"7 "Mode6"8 "Mode7"9 "Mode8"10 "Mode9"11 "Mode10"12 "Reserved"13 "Reserved"14 "Reserved"15 "Reserved";
VAL_ 263 RLM_LeftHPPWelLightSts 0 "Off"1 "On";
VAL_ 263 RLM_LeftRearfogLampSts 0 "Off"1 "On";
VAL_ 263 RLM_LeftRearfogLampFault 0 "good"1 "fault";
VAL_ 264 RLM_MidpositionLampSts 0 "Off"1 "On";
VAL_ 264 RLM_MidApositionLampFault 0 "good"1 "fault";
VAL_ 264 RLM_MidLeftTurnLampSts 0 "Off"1 "On";
VAL_ 264 RLM_MidStopLampSts 0 "Off"1 "On";
VAL_ 264 RLM_MidLeftTurnLampFault 0 "No Failure"1 "Short Circuit"2 "Open Circuit"3 "Reserved";
VAL_ 264 RLM_MidLeftStopLampFault 0 "good"1 "fault";
VAL_ 264 RLM_MidRightTurnLampSts 0 "Off"1 "On";
VAL_ 264 RLM_LicenseLampFault 0 "good"1 "fault";
VAL_ 264 RLM_LicenseLampSts 0 "Off"1 "On";
VAL_ 264 RLM_ReversingLampFault 0 "good"1 "fault";
VAL_ 264 RLM_ReverseLampSts 0 "Off"1 "On";
VAL_ 264 RLM_HighStopLampFault 0 "good"1 "fault";
VAL_ 264 RLM_HighStopLampSts 0 "Off"1 "On";
VAL_ 264 RLM_MidRightTurnLampFault 0 "No Failure"1 "Short Circuit"2 "Open Circuit"3 "Reserved";
VAL_ 264 RLM_HPPWelLightSts 0 "Off"1 "On";
VAL_ 264 RLM_WelcomeLightSts 0 "Default"1 "OFF"2 "Mode1"3 "Mode2"4 "Mode3"5 "Mode4"6 "Mode5"7 "Mode6"8 "Mode7"9 "Mode8"10 "Mode9"11 "Mode10"12 "Reserved"13 "Reserved"14 "Reserved"15 "Reserved";
VAL_ 264 RLM_MidRightPositionLampSts 0 "Off"1 "On";
VAL_ 264 RLM_MidRightPositionLampFault 0 "good"1 "fault";
VAL_ 272 HCM_RightpositionLampSts 0 "Off"1 "On";
VAL_ 272 HCM_RightpositionLampFault 0 "good"1 "fault";
VAL_ 272 HCM_RightDRLSts 0 "Off"1 "On";
VAL_ 272 HCM_RightDRLFault 0 "good"1 "fault";
VAL_ 272 HCM_RightLowBeamSts 0 "Off"1 "On";
VAL_ 272 HCM_RightLowBeamFault 0 "good"1 "fault";
VAL_ 272 HCM_RightHighBeamSts 0 "Off"1 "On";
VAL_ 272 HCM_RightHighBeamFault 0 "good"1 "fault";
VAL_ 272 HCM_hcmHeightSetRt 0 "UNDEFINEDt"1 "Level 1"2 "Level 2"3 "Level 3"4 "Level 4"5 "Level 5"6 "Reserved"7 "Reserved";
VAL_ 272 HCM_RightTurnLampSts 0 "Off"1 "On";
VAL_ 272 HCM_RightTurnLampFault 0 "No Failure"1 "Short Circuit"2 "Open Circuit"3 "Reserved";
VAL_ 272 HCM_RightHPPWelLightSts 0 "Off"1 "On";
VAL_ 272 HCM_RightWelcomeLightSts 0 "Default"1 "OFF"2 "Mode1"3 "Mode2"4 "Mode3"5 "Mode4"6 "Mode5"7 "Mode6"8 "Mode7"9 "Mode8"10 "Mode9"11 "Mode10"12 "Reserved"13 "Reserved"14 "Reserved"15 "Reserved";
VAL_ 272 HCM_rightADBModeSts 0 "Default"1 "OFF"2 "StandBy"3 "ON";
VAL_ 272 HCM_RightMatrixLEDunitFault 0 "good"1 "fault";
VAL_ 272 HCM_RightAutoHeightAdjustFault 0 "good"1 "fault";
VAL_ 272 HCM_RightAFSFault 0 "good"1 "fault";
VAL_ 272 HCM_RightInputVoltage 0 "Invalid"1 "Invalid"2 "Invalid"3 "Invalid"4 "Invalid"5 "Invalid"13 "13V";
VAL_ 272 HCM_FRFogLampSts 0 "Off"1 "On";
VAL_ 272 HCM_FRFogLampFault 0 "good"1 "fault";
VAL_ 279 RLM_RightPositionLampSts 0 "Off"1 "On";
VAL_ 279 RLM_RightPositionLampFault 0 "good"1 "fault";
VAL_ 279 RLM_RightRearfogLampSts 0 "Off"1 "On";
VAL_ 279 RLM_RightRearfogLampFault 0 "good"1 "fault";
VAL_ 279 RLM_RightReversingLampFault 0 "good"1 "fault";
VAL_ 279 RLM_RightTurnLampSts 0 "Off"1 "On";
VAL_ 279 RLM_RightStopLampSts 0 "Off"1 "On";
VAL_ 279 RLM_RightTurnLampFault 0 "No Failure"1 "Short Circuit"2 "Open Circuit"3 "Reserved";
VAL_ 279 RLM_RightStopLampFault 0 "good"1 "fault";
VAL_ 279 RLM_RightWelcomeLightSts 0 "Default"1 "OFF"2 "Mode1"3 "Mode2"4 "Mode3"5 "Mode4"6 "Mode5"7 "Mode6"8 "Mode7"9 "Mode8"10 "Mode9"11 "Mode10"12 "Reserved"13 "Reserved"14 "Reserved"15 "Reserved";
VAL_ 279 RLM_RightHPPWelLightSts 0 "Off"1 "On";
VAL_ 450 Object1_ID 0 "NoObject"255 "Invalid";
VAL_ 450 Object1_HorDis 4094 "Init"4095 "Invalid";
VAL_ 450 Object1_VerPos 4094 "Init"4095 "Invalid";
VAL_ 450 Object1_HorPosLt 4094 "Init"4095 "Invalid";
VAL_ 450 Object1_HorPosRt 4094 "Init"4095 "Invalid";
VAL_ 450 Object1_MotionType 0 "未知"1 "同向"2 "对向";
VAL_ 452 Object2_ID 0 "NoObject"255 "Invalid";
VAL_ 452 Object2_HorDis 4094 "Init"4095 "Invalid";
VAL_ 452 Object2_VerPos 4094 "Init"4095 "Invalid";
VAL_ 452 Object2_HorPosLt 4094 "Init"4095 "Invalid";
VAL_ 452 Object2_HorPosRt 4094 "Init"4095 "Invalid";
VAL_ 452 Object2_MotionType 0 "未知"1 "同向"2 "对向";
VAL_ 454 Object3_ID 0 "NoObject"255 "Invalid";
VAL_ 454 Object3_HorDis 4094 "Init"4095 "Invalid";
VAL_ 454 Object3_VerPos 4094 "Init"4095 "Invalid";
VAL_ 454 Object3_HorPosLt 4094 "Init"4095 "Invalid";
VAL_ 454 Object3_HorPosRt 4094 "Init"4095 "Invalid";
VAL_ 454 Object3_MotionType 0 "未知"1 "同向"2 "对向";
VAL_ 456 Object4_ID 0 "NoObject"255 "Invalid";
VAL_ 456 Object4_HorDis 4094 "Init"4095 "Invalid";
VAL_ 456 Object4_VerPos 4094 "Init"4095 "Invalid";
VAL_ 456 Object4_HorPosLt 4094 "Init"4095 "Invalid";
VAL_ 456 Object4_HorPosRt 4094 "Init"4095 "Invalid";
VAL_ 456 Object4_MotionType 0 "未知"1 "同向"2 "对向";
VAL_ 459 Object5_ID 0 "NoObject"255 "Invalid";
VAL_ 459 Object5_HorDis 4094 "Init"4095 "Invalid";
VAL_ 459 Object5_VerPos 4094 "Init"4095 "Invalid";
VAL_ 459 Object5_HorPosLt 4094 "Init"4095 "Invalid";
VAL_ 459 Object5_HorPosRt 4094 "Init"4095 "Invalid";
VAL_ 459 Object5_MotionType 0 "未知"1 "同向"2 "对向";
VAL_ 471 ivi_hcmHeightSet 0 "No Request"1 "Level 1"2 "Level 2"3 "Level 3"4 "Level 4"5 "Level 5"6 "Reserved"7 "Reserved";
VAL_ 471 IVI_hcmHeightAdjustSet 0 "No Request"1 "Enable"2 "Disable"3 "INVALID";
VAL_ 513 BCM_FLfoglampReq 0 "No request"1 "OFF"2 "ON"3 "Reserved";
VAL_ 513 BCM_FRfoglampReq 0 "No request"1 "OFF"2 "ON"3 "Reserved";
VAL_ 513 BCM_ComityPedLightReq 0 "No request"1 "OFF"2 "ON"3 "Reserved";
VAL_ 513 BCM_SayHiLightReq 0 "No request"1 "OFF"2 "ON"3 "Reserved";
VAL_ 513 BCM_RearLogoReq 0 "No Request"1 "OFF"2 "Dynamic"3 "Static";
VAL_ 513 BCM_ComityLightReq 0 "No request"1 "OFF"2 "Mode1"3 "Mode2"4 "Mode3"5 "Mode4"6 "Mode5"7 "Mode6"8 "Mode7"9 "Mode8"10 "Mode9"11 "Mode10"12 "Reserved"13 "Reserved"14 "Reserved"15 "Reserved";
VAL_ 513 BCM_SceneLightEffectReq 0 "No request"1 "OFF"2 "ComityPedestrian"3 "SayHi"4 "ChargeEffect"5 "ChargeProgress"6 "Mode5"7 "Mode6"8 "Mode7"9 "Mode8"10 "Mode9"11 "Mode10"12 "Reserved"13 "Reserved"14 "Reserved"15 "Reserved";
VAL_ 513 BCM_ParkLightReq 0 "No request"1 "OFF"2 "mode1"3 "mode2"4 "mode3"5 "mode4"6 "mode5"7 "mode6";
VAL_ 513 BCM_HighLightRearPosLamp 0 "No request"1 "OFF"2 "ON"3 "Reserved";
VAL_ 513 BCM_GrilleLightReq 0 "No Request"1 "OFF"2 "Dynamic"3 "Static";
VAL_ 513 BCM_StartChargeLightReq 0 "No request"1 "OFF"2 "ON"3 "Reserved";
VAL_ 513 BCM_ChargeProLightReq 0 "No request"1 "OFF"2 "ON"3 "Reserved";
VAL_ 513 BCM_PosLampModeReq 0 "No request"1 "OFF"2 "Mode1"3 "Mode2"4 "Mode3"5 "Mode4"6 "Mode5"7 "Mode6";
VAL_ 673 BCM_RMPosLampReq 0 "No request"1 "OFF"2 "ON"3 "Reserved";
VAL_ 673 BCM_FLdrlReq 0 "No request"1 "OFF"2 "ON"3 "Reserved";
VAL_ 673 BCM_EXLHeightAdjtReq 0 "No Request"1 "Level1"2 "Level2"3 "Level3"4 "Level4"5 "Level5"6 "Reserved"7 "Reserved";
VAL_ 673 BCM_ADBModeReq 0 "No Request"1 "OFF"2 "StandBy"3 "ON";
VAL_ 673 BCM_FLPosLampReq 0 "No request"1 "OFF"2 "ON"3 "Reserved";
VAL_ 673 BCM_FRdrlReq 0 "No request"1 "OFF"2 "ON"3 "Reserved";
VAL_ 673 BCM_FRPosLampReq 0 "No request"1 "OFF"2 "ON"3 "Reserved";
VAL_ 673 BCM_LowBeamReq 0 "No request"1 "OFF"2 "ON"3 "Reserved";
VAL_ 673 BCM_HighBeamReq 0 "No request"1 "OFF"2 "ON"3 "Reserved";
VAL_ 673 BCM_RearfoglampReq 0 "No request"1 "OFF"2 "ON"3 "Reserved";
VAL_ 673 BCM_LeftTurnLampReq 0 "No request"1 "OFF"2 "ON"3 "Reserved";
VAL_ 673 BCM_RightTurnLampReq 0 "No request"1 "OFF"2 "ON"3 "Reserved";
VAL_ 673 BCM_RLPosLampReq 0 "No request"1 "OFF"2 "ON"3 "Reserved";
VAL_ 673 BCM_RRPosLampReq 0 "No request"1 "OFF"2 "ON"3 "Reserved";
VAL_ 673 BCM_turnLampFlickerReq 0 "No Request"1 "LOW"2 "HIGH"3 "VERY HIGH";
VAL_ 673 BCM_turnLampSerialReq 0 "No Request"1 "Request"2 "RESERVED"3 "RESERVED";
VAL_ 673 BCM_ReversinglampReq 0 "No request"1 "OFF"2 "ON"3 "Reserved";
VAL_ 673 BCM_StoplampReq 0 "No request"1 "OFF"2 "ON"3 "Reserved";
VAL_ 673 BCM_LicenseLampReq 0 "No request"1 "OFF"2 "ON"3 "Reserved";
VAL_ 675 BCM_TurnAssistanceLamp 0 "Disable"1 "Enable";
VAL_ 675 BCM_PreviewLightEnable 0 "Disable"1 "Enable";
VAL_ 682 HVCM_ChargeState 0 "OFF"1 "Charing_Finished"2 "Discharging_Finished"3 "Battery Pre-Heating active"4 "Timer_Charging_active"5 "immeidately_Charging_active"6 "V2L DisCharging"7 "Timer_Charging_waiting"8 "SUPER CHARGE"9 "No_AC_Voltage"10 "Fualt_PlugLock"11 "Fualt_ChargingSystem"12 "Fault_ChargingStation"13 "V2V DisCharging"14 "V2G DisCharging"15 "discharge_fault"30 "Init"31 "Fault";
VAL_ 687 bcm_frontWiperSts_0x2AF 0 "Stop"1 "Low speed"2 "High speed"3 "Interrupt"4 "Wash"5 "Auto"6 "Switch_Failure"7 "Invalid";
VAL_ 705 bcm_pepsPowerMode 0 "DEFAULT_POWERMODE"1 "OFF_POWERMODE"2 "Local ON_POWERMODE"3 "Remote ON_POWERMODE"4 "RESERVE_POWERMODE1"5 "RESERVE_POWERMODE2"6 "RESERVE_POWERMODE3"7 "INVALID_POWERMODE";
VAL_ 788 ASC_LFHeight 4095 "Invalid";
VAL_ 788 ASC_RFHeight 4095 "Invalid";
VAL_ 788 ASC_LRHeight 4095 "Invalid";
VAL_ 788 ASC_RRHeight 4095 "Invalid";
VAL_ 863 Trailer_EnabState 0 "Initial"1 "Disable"2 "Enable"3 "Reserved";
VAL_ 863 Trailer_EnabStateValid 0 "Valid"1 "Invalid";
VAL_ 863 Trailer_LeftTurnLampErr 0 "No Err"1 "Err";
VAL_ 863 Trailer_RightTurnLampErr 0 "No Err"1 "Err";
VAL_ 916 pot_tailgateOpenSts 0 "Fully opened"1 "Fully closed"2 "Opening"3 "Closing"4 "PLG stopped"5 "Latch releasing"6 "Latch cinching"7 "Reserved";
VAL_ 960 BCM_WelLightTimes 0 "NoRequest"1 "OFF"2 "1"3 "2"4 "3"5 "4"6 "5"7 "6"8 "7"9 "8"10 "9"11 "10"12 "Reserved"13 "Reserved"14 "Reserved"15 "Reserved";
VAL_ 960 BCM_RearAtmoLampReq 0 "No Request"1 "OFF"2 "Dynamic"3 "Static";
VAL_ 960 BCM_WelcomeLightReq 0 "No request"1 "OFF"2 "Mode1"3 "Mode2"4 "Mode3"5 "Mode4"6 "Mode5"7 "Mode6"8 "Mode7"9 "Mode8"10 "Mode9"11 "Mode10"12 "Reserved"13 "Reserved"14 "Reserved"15 "Reserved";
VAL_ 960 BCM_HPPWelLightReq 0 "No request"1 "OFF"2 "ON"3 "Reserved";
VAL_ 960 BCM_AFSModeReq 0 "No request"1 "C"2 "E"3 "V"4 "W"5 "T"6 "Reserved"7 "Reserved";
VAL_ 960 IVI_LightShowEnable 0 "Disable"1 "Enable";
VAL_ 960 BCM_ApproachLightReq 0 "No Request"1 "OFF"2 "ON"3 "Reserved";
VAL_ 995 ebs_U_BATT 16383 "INVALID_VALUE";
VAL_ 1278 tbox_vehicleMode 0 "Initial value"1 "Normal mode"2 "Factory mode_Reserved_"3 "Transportation mode_Reserved_"4 "Collision mode_Reserved_"5 "OTA mode"6 "Reserved"7 "Reserved"8 "Reserved"9 "Reserved"10 "Reserved"11 "Reserved"12 "Reserved"13 "Reserved"14 "Reserved"15 "Invalid";
